# PIC32MK0128MCA048 register map
Vendor: Microchip
Registers are 32-bit, read-write, reset 0x0 unless marked. A register's access mark holds for its fields unless they carry their own. Addresses are absolute, and some are shared; only a register's first bit layout is shown; [hi:lo] are bit positions; {n}, {i} and the like mark numbered series.

## PORTA
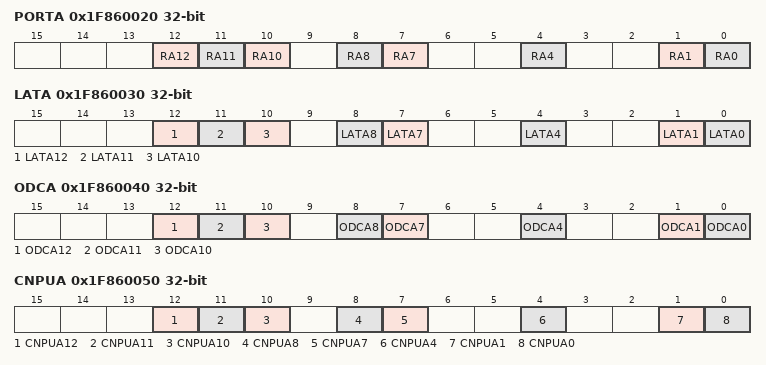
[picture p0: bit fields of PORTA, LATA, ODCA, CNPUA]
0x1F860020 PORTA reset not defined — (power-on value -------------------xxx-xx--x--xx)
  [12] RA12, [11] RA11, [10] RA10, [8] RA8, [7] RA7, [4] RA4, [1] RA1, [0] RA0
0x1F860030 LATA reset not defined — (power-on value -------------------xxx-xx--x--xx)
  [12] LATA12, [11] LATA11, [10] LATA10, [8] LATA8, [7] LATA7, [4] LATA4, [1] LATA1, [0] LATA0
0x1F860040 ODCA
  [12] ODCA12, [11] ODCA11, [10] ODCA10, [8] ODCA8, [7] ODCA7, [4] ODCA4, [1] ODCA1, [0] ODCA0
0x1F860050 CNPUA
  [12] CNPUA12, [11] CNPUA11, [10] CNPUA10, [8] CNPUA8, [7] CNPUA7, [4] CNPUA4, [1] CNPUA1, [0] CNPUA0
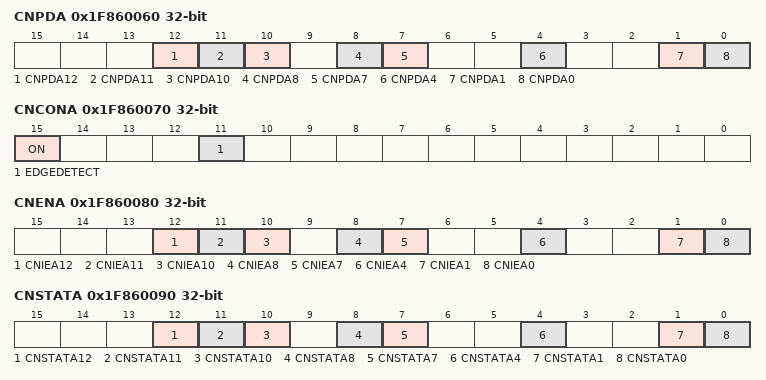
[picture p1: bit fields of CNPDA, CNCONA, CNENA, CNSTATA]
0x1F860060 CNPDA
  [12] CNPDA12, [11] CNPDA11, [10] CNPDA10, [8] CNPDA8, [7] CNPDA7, [4] CNPDA4, [1] CNPDA1, [0] CNPDA0
0x1F860070 CNCONA
  [15] ON, [11] EDGEDETECT
0x1F860080 CNENA
  [12] CNIEA12, [11] CNIEA11, [10] CNIEA10, [8] CNIEA8, [7] CNIEA7, [4] CNIEA4, [1] CNIEA1, [0] CNIEA0
0x1F860090 CNSTATA
  [12] CNSTATA12, [11] CNSTATA11, [10] CNSTATA10, [8] CNSTATA8, [7] CNSTATA7, [4] CNSTATA4, [1] CNSTATA1, [0] CNSTATA0
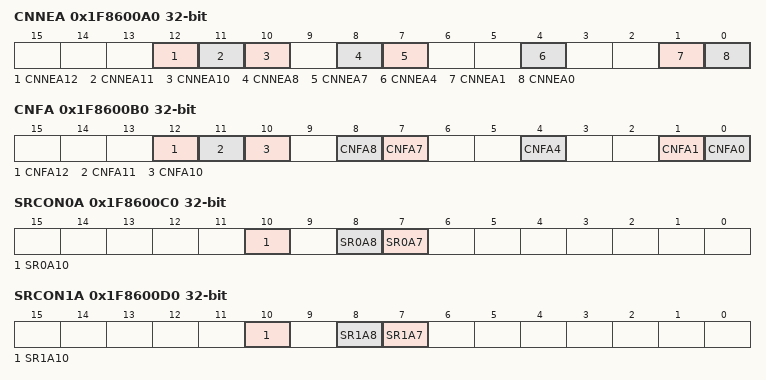
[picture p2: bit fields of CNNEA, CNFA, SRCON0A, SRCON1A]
0x1F8600A0 CNNEA
  [12] CNNEA12, [11] CNNEA11, [10] CNNEA10, [8] CNNEA8, [7] CNNEA7, [4] CNNEA4, [1] CNNEA1, [0] CNNEA0
0x1F8600B0 CNFA
  [12] CNFA12, [11] CNFA11, [10] CNFA10, [8] CNFA8, [7] CNFA7, [4] CNFA4, [1] CNFA1, [0] CNFA0
0x1F8600C0 SRCON0A
  [10] SR0A10, [8] SR0A8, [7] SR0A7
0x1F8600D0 SRCON1A
  [10] SR1A10, [8] SR1A8, [7] SR1A7

## PORTB
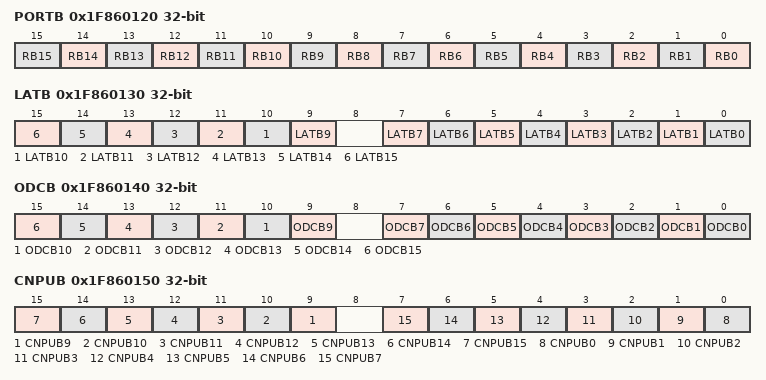
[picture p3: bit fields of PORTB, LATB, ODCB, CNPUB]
0x1F860120 PORTB reset not defined — (power-on value ----------------xxxxxxxxxxxxxxxx)
  [n] RB{n} (n=0..15)
0x1F860130 LATB reset not defined — (power-on value ----------------xxxxxxx-xxxxxxxx)
  [n] LATB{n} (n=9..15), [n] LATB{n} (n=0..7)
0x1F860140 ODCB
  [n] ODCB{n} (n=9..15), [n] ODCB{n} (n=0..7)
0x1F860150 CNPUB
  [n] CNPUB{n} (n=9..15), [n] CNPUB{n} (n=0..7)
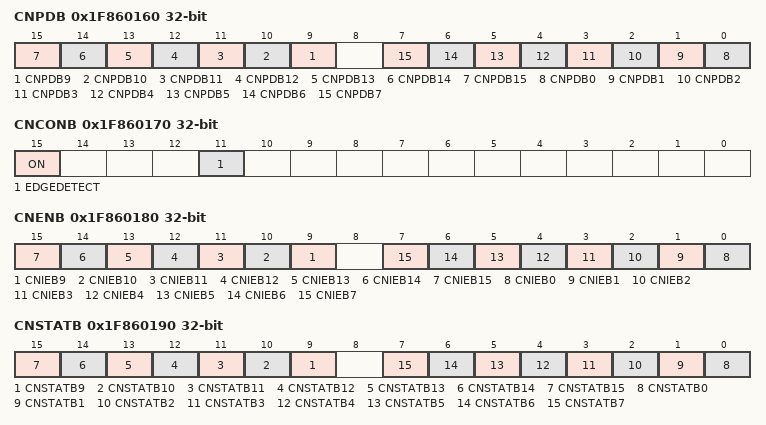
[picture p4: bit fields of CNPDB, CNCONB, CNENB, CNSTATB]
0x1F860160 CNPDB
  [n] CNPDB{n} (n=9..15), [n] CNPDB{n} (n=0..7)
0x1F860170 CNCONB
  [15] ON, [11] EDGEDETECT
0x1F860180 CNENB
  [n] CNIEB{n} (n=9..15), [n] CNIEB{n} (n=0..7)
0x1F860190 CNSTATB
  [n] CNSTATB{n} (n=9..15), [n] CNSTATB{n} (n=0..7)
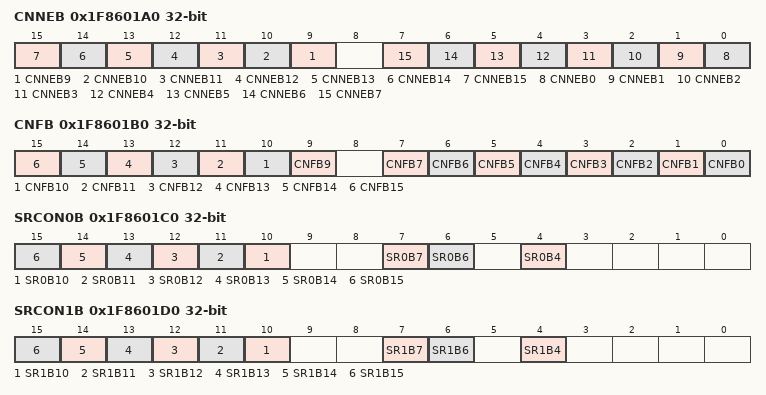
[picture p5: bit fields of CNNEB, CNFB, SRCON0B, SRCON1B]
0x1F8601A0 CNNEB
  [n] CNNEB{n} (n=9..15), [n] CNNEB{n} (n=0..7)
0x1F8601B0 CNFB
  [n] CNFB{n} (n=9..15), [n] CNFB{n} (n=0..7)
0x1F8601C0 SRCON0B
  [n] SR0B{n} (n=10..15), [7] SR0B7, [6] SR0B6, [4] SR0B4
0x1F8601D0 SRCON1B
  [n] SR1B{n} (n=10..15), [7] SR1B7, [6] SR1B6, [4] SR1B4

## PORTC
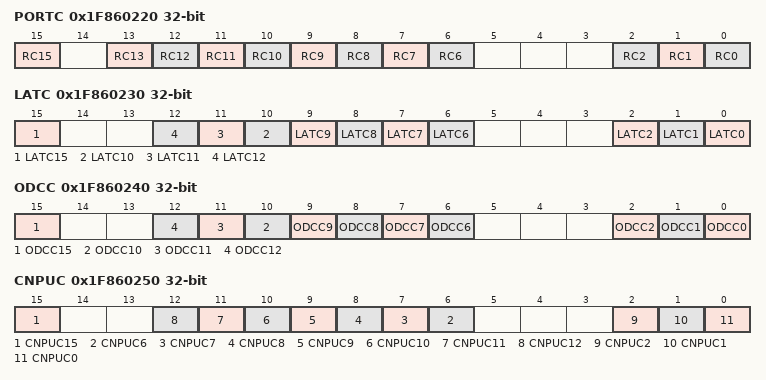
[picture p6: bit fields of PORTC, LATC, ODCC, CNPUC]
0x1F860220 PORTC reset not defined — (power-on value ----------------x-xxxxxxxx---xxx)
  [15] RC15, [n] RC{n} (n=6..13), [2] RC2, [1] RC1, [0] RC0
0x1F860230 LATC reset not defined — (power-on value ----------------x--xxxxxxx---xxx)
  [15] LATC15, [n] LATC{n} (n=6..12), [2] LATC2, [1] LATC1, [0] LATC0
0x1F860240 ODCC
  [15] ODCC15, [n] ODCC{n} (n=6..12), [2] ODCC2, [1] ODCC1, [0] ODCC0
0x1F860250 CNPUC
  [15] CNPUC15, [n] CNPUC{n} (n=6..12), [2] CNPUC2, [1] CNPUC1, [0] CNPUC0
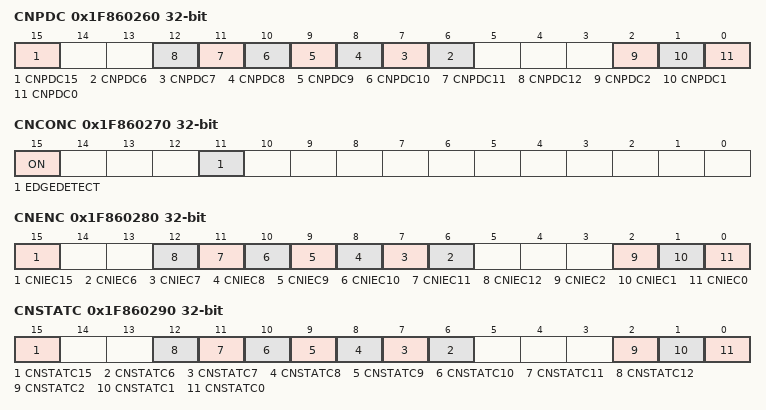
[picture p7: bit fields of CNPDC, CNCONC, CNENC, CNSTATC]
0x1F860260 CNPDC
  [15] CNPDC15, [n] CNPDC{n} (n=6..12), [2] CNPDC2, [1] CNPDC1, [0] CNPDC0
0x1F860270 CNCONC
  [15] ON, [11] EDGEDETECT
0x1F860280 CNENC
  [15] CNIEC15, [n] CNIEC{n} (n=6..12), [2] CNIEC2, [1] CNIEC1, [0] CNIEC0
0x1F860290 CNSTATC
  [15] CNSTATC15, [n] CNSTATC{n} (n=6..12), [2] CNSTATC2, [1] CNSTATC1, [0] CNSTATC0
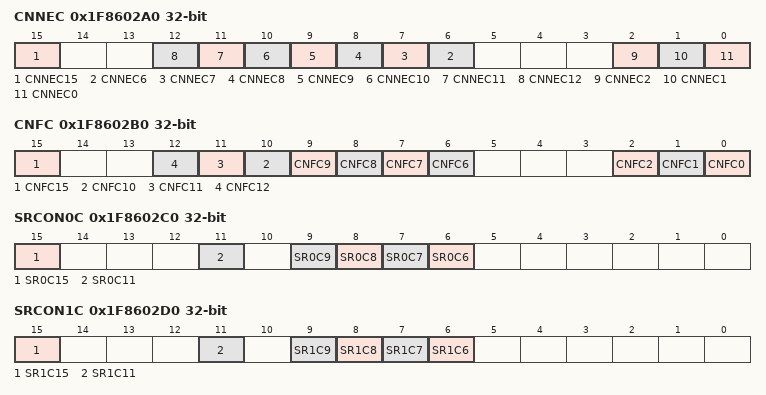
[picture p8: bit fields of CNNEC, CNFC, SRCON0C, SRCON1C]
0x1F8602A0 CNNEC
  [15] CNNEC15, [n] CNNEC{n} (n=6..12), [2] CNNEC2, [1] CNNEC1, [0] CNNEC0
0x1F8602B0 CNFC
  [15] CNFC15, [n] CNFC{n} (n=6..12), [2] CNFC2, [1] CNFC1, [0] CNFC0
0x1F8602C0 SRCON0C
  [15] SR0C15, [11] SR0C11, [n] SR0C{n} (n=6..9)
0x1F8602D0 SRCON1C
  [15] SR1C15, [11] SR1C11, [n] SR1C{n} (n=6..9)

## PORTD
0x1F860320 PORTD reset not defined — (power-on value -----------------------x--------)
  [8] RD8
0x1F860330 LATD reset not defined — (power-on value -----------------------x--------)
  [8] LATD8
0x1F860340 ODCD
  [8] ODCD8
0x1F860350 CNPUD
  [8] CNPUD8
0x1F860360 CNPDD
  [8] CNPDD8
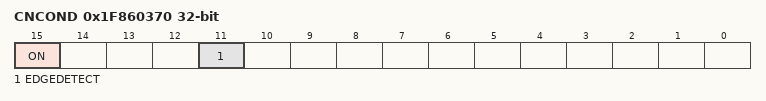
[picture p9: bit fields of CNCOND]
0x1F860370 CNCOND
  [15] ON, [11] EDGEDETECT
0x1F860380 CNEND
  [8] CNIED8
0x1F860390 CNSTATD
  [8] CNSTATD8
0x1F8603A0 CNNED
  [8] CNNED8
0x1F8603B0 CNFD
  [8] CNFD8
0x1F8603C0 SRCON0D
  [8] SR0D8
0x1F8603D0 SRCON1D
  [8] SR1D8
